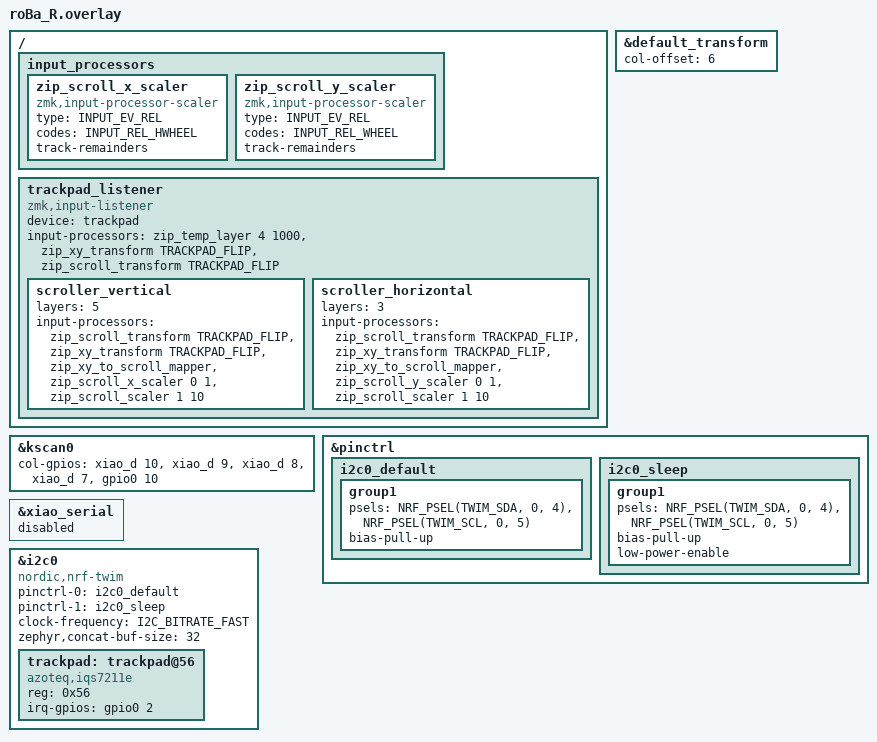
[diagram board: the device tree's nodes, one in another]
#include "roBa.dtsi"
#include <input/processors.dtsi>
#include <dt-bindings/zmk/input_transform.h>
#include <zephyr/dt-bindings/input/input-event-codes.h>

/* トラックパッドの取り付け向き補正（180度回転 = X・Y とも反転） */
#define TRACKPAD_FLIP (INPUT_TRANSFORM_X_INVERT | INPUT_TRANSFORM_Y_INVERT)

/* --- 右手側の列オフセット --- */
&default_transform {
    col-offset = <6>;
};

/* --- 右手側の keyscan カラム定義 --- */
&kscan0 {
    col-gpios
        = <&xiao_d 10 GPIO_ACTIVE_HIGH>
        , <&xiao_d  9 GPIO_ACTIVE_HIGH>
        , <&xiao_d  8 GPIO_ACTIVE_HIGH>
        , <&xiao_d  7 GPIO_ACTIVE_HIGH>
        , <&gpio0  10 GPIO_ACTIVE_HIGH>
        ;
};

/* --- I2C ピン設定（IQS7211E トラックパッド用）SDA=D4(P0.04) SCL=D5(P0.05) --- */
&pinctrl {
    i2c0_default: i2c0_default {
        group1 {
            psels =
                <NRF_PSEL(TWIM_SDA, 0, 4)>,
                <NRF_PSEL(TWIM_SCL, 0, 5)>;
            bias-pull-up;
        };
    };

    i2c0_sleep: i2c0_sleep {
        group1 {
            psels =
                <NRF_PSEL(TWIM_SDA, 0, 4)>,
                <NRF_PSEL(TWIM_SCL, 0, 5)>;
            bias-pull-up;
            low-power-enable;
        };
    };
};

/* UART は使わないので無効化 */
&xiao_serial {
    status = "disabled";
};

/* --- I2C0 + IQS7211E トラックパッド本体 --- */
&i2c0 {
    status = "okay";
    compatible = "nordic,nrf-twim";
    pinctrl-0 = <&i2c0_default>;
    pinctrl-1 = <&i2c0_sleep>;
    pinctrl-names = "default", "sleep";
    clock-frequency = <I2C_BITRATE_FAST>;
    zephyr,concat-buf-size = <32>;

    trackpad: trackpad@56 {
        status = "okay";
        compatible = "azoteq,iqs7211e";
        reg = <0x56>;

        /* RDY ピン: D0 (P0.02) */
        irq-gpios = <&gpio0 2 GPIO_PULL_UP>;
    };
};

/* --- Input Processor 定義（X/Y 別スクロールスケーラー） --- */
 / {
    input_processors {
        /* 水平スクロール用スケーラー（X方向） */
        zip_scroll_x_scaler: zip_scroll_x_scaler {
            compatible = "zmk,input-processor-scaler";
            #input-processor-cells = <2>;
            type = <INPUT_EV_REL>;
            codes = <INPUT_REL_HWHEEL>;
            track-remainders;
        };

        /* 垂直スクロール用スケーラー（Y方向） */
        zip_scroll_y_scaler: zip_scroll_y_scaler {
            compatible = "zmk,input-processor-scaler";
            #input-processor-cells = <2>;
            type = <INPUT_EV_REL>;
            codes = <INPUT_REL_WHEEL>;
            track-remainders;
        };
    };

    /* --- トラックパッド Listener (AML + スクロール) --- */
    trackpad_listener: trackpad_listener {
        compatible = "zmk,input-listener";
        status = "okay";
        device = <&trackpad>;

        /*
         * トラックパッドを上下逆（180度回転）に取り付けているため、
         * カーソル (REL_X/Y) と2本指スクロール (WHEEL/HWHEEL) の両方を反転する。
         * 上下だけが逆の場合は TRACKPAD_FLIP から INPUT_TRANSFORM_X_INVERT を外す。
         * 1) 触れたら MOUSE レイヤー (4) を 1000ms オン
         * 2) カーソル反転  3) 2本指スクロール反転
         */
        input-processors = <
            &zip_temp_layer 4 1000
            &zip_xy_transform TRACKPAD_FLIP
            &zip_scroll_transform TRACKPAD_FLIP
        >;

        /* ===== レイヤー 5: 縦スクロール専用（上下のみ） ===== */
        scroller_vertical {
            layers = <5>;
            input-processors = <
                &zip_scroll_transform TRACKPAD_FLIP  /* 2本指スクロールの反転（mapper より前） */
                &zip_xy_transform TRACKPAD_FLIP      /* 1本指移動の反転 */
                &zip_xy_to_scroll_mapper
                &zip_scroll_x_scaler 0 1   /* X = 0倍 → 横スクロール殺す */
                &zip_scroll_scaler 1 10    /* 全体 1/10 でフニャ軽減 */
            >;
        };

        /* ===== レイヤー 2: 横スクロール専用（左右のみ） ===== */
        scroller_horizontal {
            layers = <3>;
            input-processors = <
                &zip_scroll_transform TRACKPAD_FLIP  /* 2本指スクロールの反転（mapper より前） */
                &zip_xy_transform TRACKPAD_FLIP      /* 1本指移動の反転 */
                &zip_xy_to_scroll_mapper
                &zip_scroll_y_scaler 0 1   /* Y = 0倍 → 縦スクロール殺す */
                &zip_scroll_scaler 1 10    /* 少しだけ動く横スクロール */
            >;
        };
    };
};
